# Polarfire SoC register map
Vendor: Microchip; File version: 1.0
CPU: Microchip PolarFire SoC 1.0, little endian
Registers are 32-bit, read-write, reset 0x0 unless marked. A register's access mark holds for its fields unless they carry their own. Offsets are from the block's base; [hi:lo] are bit positions.

## MSRTC_LO — MSRTC_LO Controller
Base 0x20124000
Same registers: MSRTC_HI 0x28124000
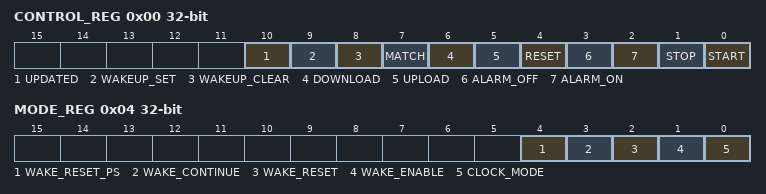
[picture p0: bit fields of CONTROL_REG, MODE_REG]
0x00 CONTROL_REG
  [10] UPDATED — 1:when RTC counter updates the RTC value.It is cleared by the writing '1' to the bit
  [9] WAKEUP_SET — 1:Assert the rtc_wakeup output and set the wakeup status bit.
  [8] WAKEUP_CLEAR — Set every time a match occurs.1:wakeup_clear bit is cleared. Once cleared it will not be set again until the next wakeup occurs
  [7] MATCH ro — RTC value matches with wakeup value. Indicates rtc_match output value.
  [6] DOWNLOAD — 1: Current RTC counter value to be downloaded
  [5] UPLOAD — 1: Date/time value loaded into date/time registers and uploaded to the RTC counters
  [4] RESET — 1:date/time value is reset and uploaded to RTC counters
  [3] ALARM_OFF — 1:Alarm is disabled
  [2] ALARM_ON — 1:Alarm is enabled
  [1] STOP — When stop bit is written '1', RTC counter is stopped. Read indicates that RTC is running
  [0] START — When start bit is written '1',indicates that RTC counter is started. Read indicates that RTC counter is running.
0x04 MODE_REG
  [4] WAKE_RESET_PS — when a wakeup occurs reset the pre-scaler
  [3] WAKE_CONTINUE — when a wakeup occurs continue counting
  [2] WAKE_RESET — when a wakeup occurs reset the RTC counters
  [1] WAKE_ENABLE — Enables the wakeup output
  [0] CLOCK_MODE — 0: Binary counter 1: date and time counting
0x08 PRESCALER_REG
  [25:0] PRESCALER — value to divide incoming rtc clock. It should be set to achieve 1Hz from rtc_clk. Value must be greater than 1. Value = Clock Frequency - 1Hz
0x0C ALARM_LOWER_REG
  [31:0] ALARM_LOWER — Write: Sets the alarm wakeup time. Read: Returns the alarm time. Binary count [31:0]
0x10 ALARM_UPPER_REG
  [10:0] ALARM_UPPER — Write: sets the alarm wakeup time. Read: returns the alarm time. Binary count [42:32]
0x14 COMPARE_LOWER_REG
  [31:0] COMPARE_LOWER — Write: sets the compare bits on the alarm time. [7:0]: Seconds, [15:8]: Minutres, [23:16]: Hours, [31:24]:Day. Read: Returns the compare value. 0: Bit is ignored. 1: Bit is compared.
0x18 COMPARE_UPPER_REG
  [29:0] COMPARE_UPPER — Write: sets the compare bits on the alarm time. [7:0]: Month, [15:8]: Year, [23:16]: Weekday, [29:24]:Week. Read: Returns the compare value. 0: Bit is ignored. 1: Bit is compared.
0x20 DATE_TIME_LOWER_REG
  [31:0] DATETIME_LOWER — Writes: Data to be uploaded to counter. Read: returns the current time. [7:0]: Seconds, [15:8]: Minutres, [23:16]: Hours, [31:24]:Day.
0x24 DATE_TIME_UPPER_REG
  [29:0] DATETIME_UPPER — Writes: Data to be uploaded to counter. Read: returns the upper time bits that are in alignment with the last read lower bits.[7:0]: Month, [15:8]: Year, [23:16]: Weekday, [29:24]:Week.
0x30 SECONDS_REG
  [5:0] SECONDS — The complete RTC data is read and stored internally. For writes all fields (0x30-x4c) must be written. The control register upload bit will upload data to the RTC.These registers are for use when clock_mode=1
0x34 MINUTES_REG
  [5:0] MINUTES
0x38 HOURS_REG
  [4:0] HOURS
0x3C DAY_REG
  [4:0] DAY
0x40 MONTH_REG
  [3:0] MONTH
0x44 YEAR_REG
  [7:0] YEAR
0x48 WEEKDAY_REG
  [2:0] WEEKDAY
0x4C WEEK_REG
  [5:0] WEEK
0x50 SECONDS_CNT_REG
  [5:0] SECONDS — Each read returns the current date/time value. It is possible that date/time may increament b/w reads. Write: All fields (0x50-0x6c) must be writeen. The control register upload bit will upload the data to RTC.These registers are for use when clock_mode=1
0x54 MINUTES_CNT_REG
  [5:0] MINUTES
0x58 HOURS_CNT_REG
  [4:0] HOURS
0x5C DAY_CNT_REG
  [4:0] DAY
0x60 MONTH_CNT_REG
  [3:0] MONTH
0x64 YEAR_CNT_REG
  [7:0] YEAR
0x68 WEEKDAY_CNT_REG
  [2:0] WEEKDAY
0x6C WEEK_CNT_REG
  [5:0] WEEK
